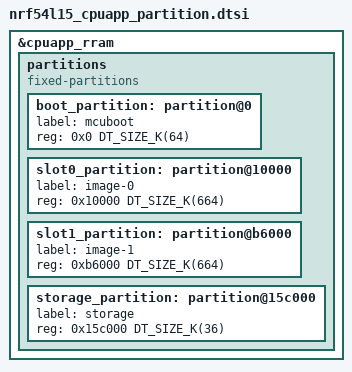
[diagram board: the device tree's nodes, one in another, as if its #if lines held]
/*
 * Copyright (c) 2025 Nordic Semiconductor ASA
 *
 * SPDX-License-Identifier: Apache-2.0
 */

&cpuapp_rram {
	partitions {
		compatible = "fixed-partitions";
		#address-cells = <1>;
		#size-cells = <1>;
		ranges;

		boot_partition: partition@0 {
			label = "mcuboot";
			reg = <0x0 DT_SIZE_K(64)>;
		};

#ifdef WITH_FLPR_PARTITIONS
		slot0_partition: partition@10000 {
			label = "image-0";
			reg = <0x10000 DT_SIZE_K(664)>;
		};

		slot1_partition: partition@b6000 {
			label = "image-1";
			reg = <0xb6000 DT_SIZE_K(664)>;
		};

		storage_partition: partition@15c000 {
			label = "storage";
			reg = <0x15c000 DT_SIZE_K(36)>;
		};
#else
		slot0_partition: partition@10000 {
			label = "image-0";
			reg = <0x10000 DT_SIZE_K(712)>;
		};

		slot1_partition: partition@c2000 {
			label = "image-1";
			reg = <0xc2000 DT_SIZE_K(712)>;
		};

		storage_partition: partition@174000 {
			label = "storage";
			reg = <0x174000 DT_SIZE_K(36)>;
		};
#endif
	};
};
